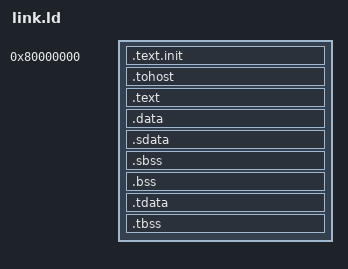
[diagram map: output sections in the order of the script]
/*======================================================================*/
/* Proxy kernel linker script                                           */
/*======================================================================*/
/* This is the linker script used when building the proxy kernel. */

/*----------------------------------------------------------------------*/
/* Setup                                                                */
/*----------------------------------------------------------------------*/

/* The OUTPUT_ARCH command specifies the machine architecture where the
   argument is one of the names used in the BFD library. More
   specifically one of the entires in bfd/cpu-mips.c */

OUTPUT_ARCH( "riscv" )
ENTRY(_start)

/*----------------------------------------------------------------------*/
/* Sections                                                             */
/*----------------------------------------------------------------------*/

SECTIONS
{

  /* text: test code section */
  . = 0x80000000;
  .text.init : { *(.text.init) }

  .tohost ALIGN(0x1000) : { *(.tohost) }

  .text : { *(.text) }

  /* data segment */
  .data ALIGN(0x40) : { *(.data) }

  .sdata : {
    __global_pointer$ = . + 0x800;
    *(.srodata.cst16) *(.srodata.cst8) *(.srodata.cst4) *(.srodata.cst2) *(.srodata*)
    *(.sdata .sdata.* .gnu.linkonce.s.*)
  }

  /* bss segment */
  .sbss : {
    PROVIDE(__bss_start = .);
    *(.sbss .sbss.* .gnu.linkonce.sb.*)
    *(.scommon)
    PROVIDE(__bss_end = .);
  }
  .bss ALIGN(0x40) : { *(.bss) }

  /* thread-local data segment */
  .tdata :
  {
    PROVIDE(__tdata_start = .);
    _tls_data = .;
    *(.tdata.begin)
    *(.tdata)
    *(.tdata.end)
  }
  .tbss :
  {
    *(.tbss)
    *(.tbss.end)
  }

  /* End of uninitalized data segement */
    . = ALIGN (4K);
    PROVIDE (_end = .);
}

